# ADuCM4050 register map
Vendor: Analog Devices; Series: ADuCM4050; File version: 1p0
CPU: CM4 r0p1, little endian, MPU, FPU, 3 interrupt priority bits
Registers are 32-bit, read-write, reset 0x0 unless marked. A register's access mark holds for its fields unless they carry their own. Offsets are from the block's base; [hi:lo] are bit positions.

## FLCC0 — Flash Controller
Base 0x40018000
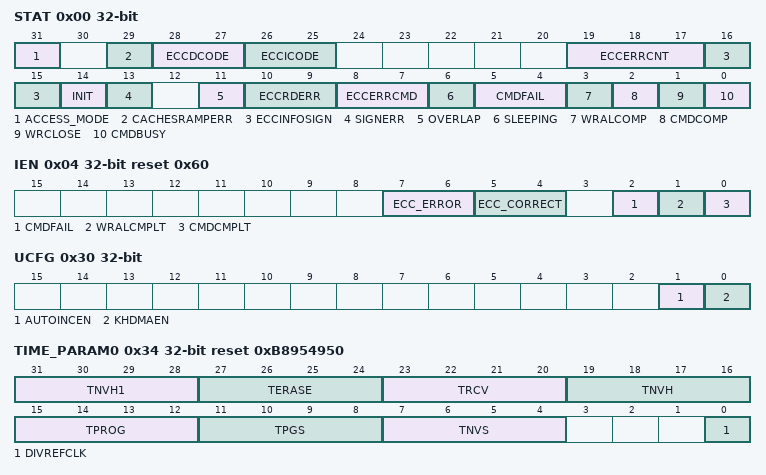
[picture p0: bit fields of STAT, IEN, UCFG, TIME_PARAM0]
0x00 STAT — Status
  [31] ACCESS_MODE ro
    0=Direct (Flash controller is currently in Direct Access mode; user access to all registers is enabled); 1=Indirect (Flash Controller is currently in Indirect Access mode; user access to registers is limited to read-only access of the status register. Full register access will be restored when the Cryptographic module releases control of the flash controller (crypto completes the ongoing operation within the protected key storage region))
  [29] CACHESRAMPERR ro — SRAM parity errors in Cache Controller
  [28:27] ECCDCODE ro — DCode AHB Bus Error ECC status
  [26:25] ECCICODE ro — ICode AHB Bus Error ECC status
  [19:17] ECCERRCNT ro — ECC correction counter
  [16:15] ECCINFOSIGN ro — ECC status of flash initialization
  [14] INIT ro — Flash controller initialization in progress
  [13] SIGNERR ro — Signature check failure during initialization
  [11] OVERLAP range 0x00000000..0x00000001 — Overlapping Command
  [10:9] ECCRDERR ro — ECC IRQ cause
  [8:7] ECCERRCMD ro — ECC errors detected during user issued SIGN command
  [6] SLEEPING ro — Flash array is in low power (sleep) mode
  [5:4] CMDFAIL ro — Provides information on command failures
  [3] WRALCOMP ro — Write almost complete
  [2] CMDCOMP ro — Command complete
  [1] WRCLOSE ro — WRITE registers are closed
  [0] CMDBUSY ro — Command busy
0x04 IEN reset 0x60 — Interrupt Enable
  [7:6] ECC_ERROR — Control whether to generate bus errors, interrupts, or neither in response to 2-bit ECC Error events
    0=NONE_err (Do not generate a response to ECC events); 1=BUS_ERR_err (Generate Bus Errors in response to ECC events); 2=IRQ_err (Generate IRQs in response to ECC events)
  [5:4] ECC_CORRECT — Control whether to generate bus errors, interrupts, or neither in response to 1-bit ECC Correction events
    0=NONE_cor (Do not generate a response to ECC events); 1=BUS_ERR_cor (Generate Bus Errors in response to ECC events); 2=IRQ_cor (Generate IRQs in response to ECC events)
  [2] CMDFAIL range 0x00000000..0x00000001 — Command fail interrupt enable
  [1] WRALCMPLT range 0x00000000..0x00000001 — Write almost complete interrupt enable
  [0] CMDCMPLT range 0x00000000..0x00000001 — Command complete interrupt enable
0x08 CMD — Command
  [3:0] VALUE — Commands
    0=IDLE; 1=ABORT; 2=SLEEP (Requests flash to enter Sleep mode); 3=SIGN; 4=WRITE; 5=BLANK_CHECK (Checks all of User Space; fails if any bits in user space are cleared); 6=ERASEPAGE; 7=MASSERASE
0x0C KH_ADDR — Write Address
  [19:3] VALUE range 0x00000000..0x0001FFFF — Address to be written on a WRITE command
0x10 KH_DATA0 reset 0xFFFFFFFF — Write Lower Data
  [31:0] VALUE range 0x00000000..0xFFFFFFFF — Lower half of 64-bit dual word data to be written on a Write command
0x14 KH_DATA1 reset 0xFFFFFFFF — Write Upper Data
  [31:0] VALUE range 0x00000000..0xFFFFFFFF — Upper half of 64-bit dual word data to be written on a Write command
0x18 PAGE_ADDR0 — Lower Page Address
  [19:10] VALUE range 0x00000000..0x000003FF — Lower address bits of the page address
0x1C PAGE_ADDR1 — Upper Page Address
  [19:10] VALUE range 0x00000000..0x000003FF — Upper address bits of the page address
0x20 KEY
  [31:0] VALUE wo — Key register
0x24 WR_ABORT_ADDR — Write Abort Address
  [31:0] VALUE ro — Address of recently aborted write command
0x28 WRPROT reset 0xFFFFFFFF — Write Protection
  [31:0] WORD range 0x00000000..0xFFFFFFFF — Clear bits to write protect related groups of user space pages
0x2C SIGNATURE
  [31:0] VALUE ro — Read signature
0x30 UCFG — User Configuration
  [1] AUTOINCEN range 0x00000000..0x00000001 — Auto Address Increment for Key Hole Access
  [0] KHDMAEN range 0x00000000..0x00000001 — Key hole DMA enable
0x34 TIME_PARAM0 reset 0xB8954950 — Time Parameter 0
  [31:28] TNVH1 range 0x00000000..0x0000000F — NVSTR Hold time during Mass Erase
  [27:24] TERASE range 0x00000000..0x0000000F — Erase Time
  [23:20] TRCV range 0x00000000..0x0000000F — Recovery time
  [19:16] TNVH range 0x00000000..0x0000000F — NVSTR Hold time
  [15:12] TPROG range 0x00000000..0x0000000F — Program time
  [11:8] TPGS range 0x00000000..0x0000000F — NVSTR to Program setup time
  [7:4] TNVS range 0x00000000..0x0000000F — PROG/ERASE to NVSTR setup time
  [0] DIVREFCLK range 0x00000000..0x00000001 — Divide Reference Clock (by 2)
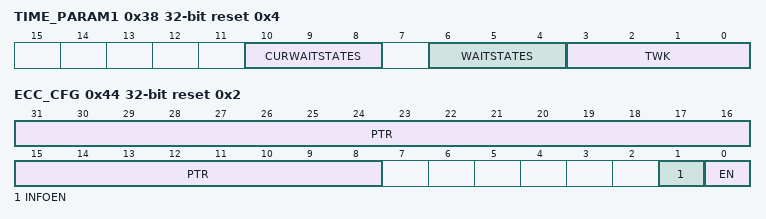
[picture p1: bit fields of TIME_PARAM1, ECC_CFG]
0x38 TIME_PARAM1 reset 0x4 — Time Parameter 1
  [10:8] CURWAITSTATES ro — Current wait states [2:0]
  [6:4] WAITSTATES range 0x00000000..0x00000007 — Number of wait states to access flash
  [3:0] TWK range 0x00000000..0x0000000F — Wake up time
0x3C ABORT_EN_LO — IRQ Abort Enable (Lower Bits)
  [31:0] VALUE range 0x00000000..0xFFFFFFFF — VALUE[31:0] Sys IRQ Abort Enable
0x40 ABORT_EN_HI — IRQ Abort Enable (Upper Bits)
  [31:0] VALUE range 0x00000000..0xFFFFFFFF — VALUE[63:32] Sys IRQ Abort Enable
0x44 ECC_CFG reset 0x2 — ECC Configuration
  [31:8] PTR range 0x00000000..0x00FFFFFF — ECC start page pointer
  [1] INFOEN range 0x00000000..0x00000001 — Info space ECC Enable bit
  [0] EN range 0x00000000..0x00000001 — ECC Enable
0x48 ECC_ADDR — ECC Status (Address)
  [19:0] VALUE ro — This register has the address for which ECC error is detected
0x50 POR_SEC — Flash Security
  [0] SECURE range 0x00000000..0x00000001 — Set this bit to prevent read or write access to User Space (sticky when set)
0x54 VOL_CFG reset 0x1 — Volatile Flash Configuration
  [0] INFO_REMAP range 0x00000000..0x00000001 — Alias the info space to the base address of user space
